# GD32VF103 register map
File version: 1.0
CPU: CM3 r2p1, little endian, no MPU, no FPU, 4 interrupt priority bits
Registers are 32-bit, read-write, reset 0x0 unless marked. A register's access mark holds for its fields unless they carry their own. Offsets are from the block's base; [hi:lo] are bit positions; {n}, {i} and the like mark numbered series.

## FMC
Base 0x40022000
0x00 WS — wait state counter register
  [2:0] WSCNT
0x04 KEY0 wo — Unlock key register 0
  [31:0] KEY — FMC_CTL0 unlock key
0x08 OBKEY wo — Option byte unlock key register
  [31:0] OBKEY — FMC_ CTL0 option byte operation unlock register
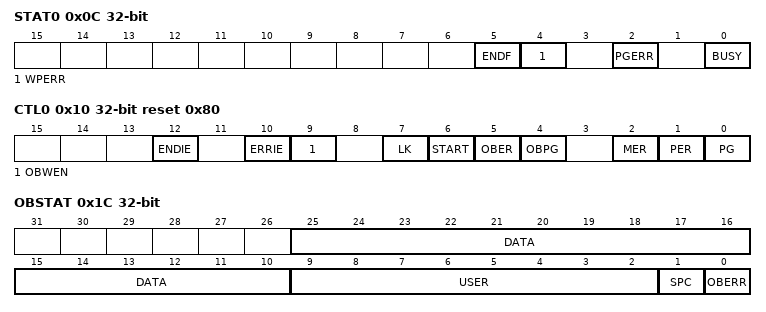
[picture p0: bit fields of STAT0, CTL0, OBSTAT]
0x0C STAT0 access per field — Status register 0
  [5] ENDF rw — End of operation flag bit
  [4] WPERR rw — Erase/Program protection error flag bit
  [2] PGERR rw — Program error flag bit
  [0] BUSY ro — The flash is busy bit
0x10 CTL0 reset 0x80 — Control register 0
  [12] ENDIE — End of operation interrupt enable bit
  [10] ERRIE — Error interrupt enable bit
  [9] OBWEN — Option byte erase/program enable bit
  [7] LK — FMC_CTL0 lock bit
  [6] START — Send erase command to FMC bit
  [5] OBER — Option bytes erase command bit
  [4] OBPG — Option bytes program command bit
  [2] MER — Main flash mass erase for bank0 command bit
  [1] PER — Main flash page erase for bank0 command bit
  [0] PG — Main flash program for bank0 command bit
0x14 ADDR0 wo — Address register 0
  [31:0] ADDR — Flash erase/program command address bits
0x1C OBSTAT ro — Option byte status register
  [25:10] DATA — Store DATA[15:0] of option bytes block after system reset
  [9:2] USER — Store USER of option bytes block after system reset
  [1] SPC — Option bytes security protection code
  [0] OBERR — Option bytes read error bit
0x20 WP ro — Erase/Program Protection register
  [31:0] WP — Store WP[31:0] of option bytes block after system reset
0x100 PID ro — Product ID register
  [31:0] PID — Product reserved ID code register

## FWDGT — free watchdog timer
Base 0x40003000
0x00 CTL wo — Control register
  [15:0] CMD — Key value
0x04 PSC — Prescaler register
  [2:0] PSC — Free watchdog timer prescaler selection
0x08 RLD reset 0xFFF — Reload register
  [11:0] RLD — Free watchdog timer counter reload value
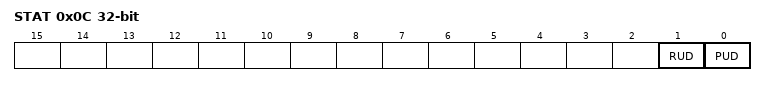
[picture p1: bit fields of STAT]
0x0C STAT ro — Status register
  [1] RUD — Free watchdog timer counter reload value update
  [0] PUD — Free watchdog timer prescaler value update

## GPIOA — General-purpose I/Os
Base 0x40010800
Same registers: GPIOB 0x40010C00, GPIOC 0x40011000, GPIOD 0x40011400, GPIOE 0x40011800
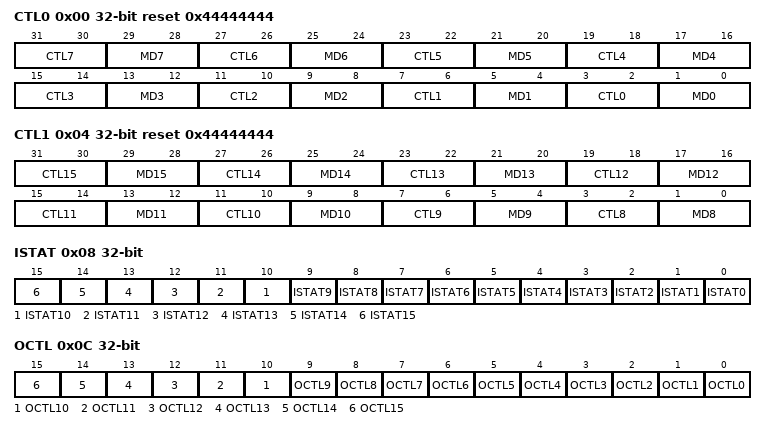
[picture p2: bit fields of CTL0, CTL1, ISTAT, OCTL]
0x00 CTL0 reset 0x44444444 — port control register 0
  [4n+3:4n+2] CTL{n} (n=0..7) — Port x configuration bits (x = {n})
  [4n+1:4n] MD{n} (n=4..7) — Port x mode bits (x = {n})
  [13:12] MD3 — Port x mode bits (x = 3 )
  [9:8] MD2 — Port x mode bits (x = 2 )
  [5:4] MD1 — Port x mode bits (x = 1)
  [1:0] MD0 — Port x mode bits (x = 0)
0x04 CTL1 reset 0x44444444 — port control register 1
  [4n-29:4n-30] CTL{n} (n=8..15) — Port x configuration bits (x = {n})
  [4n-31:4n-32] MD{n} (n=12..15) — Port x mode bits (x = {n})
  [13:12] MD11 — Port x mode bits (x = 11 )
  [9:8] MD10 — Port x mode bits (x = 10 )
  [5:4] MD9 — Port x mode bits (x = 9)
  [1:0] MD8 — Port x mode bits (x = 8)
0x08 ISTAT ro — Port input status register
  [n] ISTAT{n} (n=0..15) — Port input status
0x0C OCTL — Port output control register
  [n] OCTL{n} (n=0..15) — Port output control
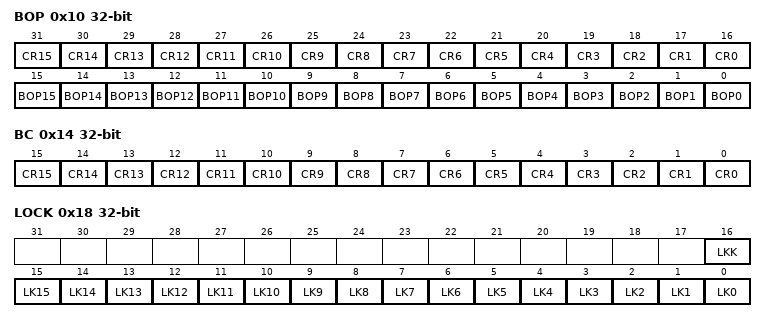
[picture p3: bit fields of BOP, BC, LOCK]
0x10 BOP wo — Port bit operate register
  [n+16] CR{n} (n=0..15) — Port {n} Clear bit
  [n] BOP{n} (n=0..15) — Port {n} Set bit
0x14 BC wo — Port bit clear register
  [n] CR{n} (n=0..15) — Port {n} Clear bit
0x18 LOCK — GPIO port configuration lock register
  [16] LKK — Lock sequence key
  [n] LK{n} (n=0..15) — Port Lock bit {n}

## I2C0 — Inter integrated circuit
Base 0x40005400
Same registers: I2C1 0x40005800
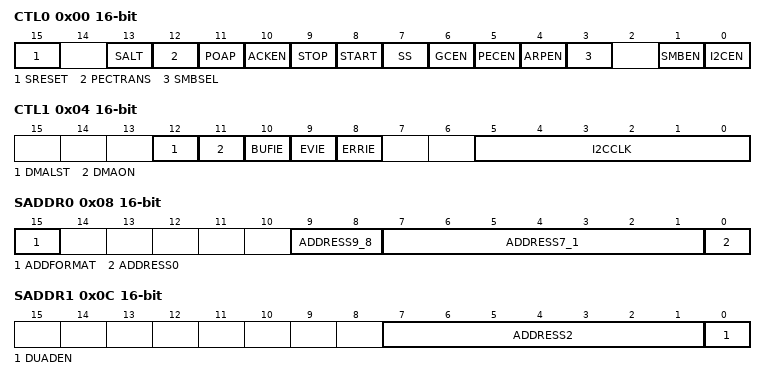
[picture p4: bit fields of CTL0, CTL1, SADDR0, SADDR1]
0x00 CTL0 16-bit — Control register 0
  [15] SRESET — Software reset
  [13] SALT — SMBus alert
  [12] PECTRANS — PEC Transfer
  [11] POAP — Position of ACK and PEC when receiving
  [10] ACKEN — Whether or not to send an ACK
  [9] STOP — Generate a STOP condition on I2C bus
  [8] START — Generate a START condition on I2C bus
  [7] SS — Whether to stretch SCL low when data is not ready in slave mode
  [6] GCEN — Whether or not to response to a General Call (0x00)
  [5] PECEN — PEC Calculation Switch
  [4] ARPEN — ARP protocol in SMBus switch
  [3] SMBSEL — SMBusType Selection
  [1] SMBEN — SMBus/I2C mode switch
  [0] I2CEN — I2C peripheral enable
0x04 CTL1 16-bit — Control register 1
  [12] DMALST — Flag indicating DMA last transfer
  [11] DMAON — DMA mode switch
  [10] BUFIE — Buffer interrupt enable
  [9] EVIE — Event interrupt enable
  [8] ERRIE — Error interrupt enable
  [5:0] I2CCLK — I2C Peripheral clock frequency
0x08 SADDR0 16-bit — Slave address register 0
  [15] ADDFORMAT — Address mode for the I2C slave
  [9:8] ADDRESS9_8 — Highest two bits of a 10-bit address
  [7:1] ADDRESS7_1 — 7-bit address or bits 7:1 of a 10-bit address
  [0] ADDRESS0 — Bit 0 of a 10-bit address
0x0C SADDR1 16-bit — Slave address register 1
  [7:1] ADDRESS2 — Second I2C address for the slave in Dual-Address mode
  [0] DUADEN — Dual-Address mode switch
0x10 DATA 16-bit — Transfer buffer register
  [7:0] TRB — Transmission or reception data buffer register
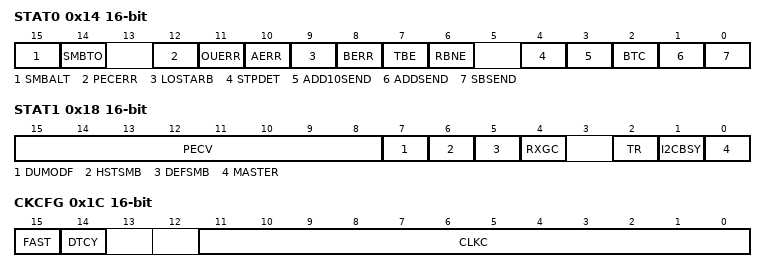
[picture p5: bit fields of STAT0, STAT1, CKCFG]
0x14 STAT0 16-bit access per field — Transfer status register 0
  [15] SMBALT rw — SMBus Alert status
  [14] SMBTO rw — Timeout signal in SMBus mode
  [12] PECERR rw — PEC error when receiving data
  [11] OUERR rw — Over-run or under-run situation occurs in slave mode
  [10] AERR rw — Acknowledge error
  [9] LOSTARB rw — Arbitration Lost in master mode
  [8] BERR rw — A bus error occurs indication a unexpected START or STOP condition on I2C bus
  [7] TBE ro — I2C_DATA is Empty during transmitting
  [6] RBNE ro — I2C_DATA is not Empty during receiving
  [4] STPDET ro — STOP condition detected in slave mode
  [3] ADD10SEND ro — Header of 10-bit address is sent in master mode
  [2] BTC ro — Byte transmission completed
  [1] ADDSEND ro — Address is sent in master mode or received and matches in slave mode
  [0] SBSEND ro — START condition sent out in master mode
0x18 STAT1 16-bit ro — Transfer status register 1
  [15:8] PECV — Packet Error Checking Value that calculated by hardware when PEC is enabled
  [7] DUMODF — Dual Flag in slave mode
  [6] HSTSMB — SMBus Host Header detected in slave mode
  [5] DEFSMB — Default address of SMBusDevice
  [4] RXGC — General call address (00h) received
  [2] TR — Whether the I2C is a transmitter or a receiver
  [1] I2CBSY — Busy flag
  [0] MASTER — A flag indicating whether I2C block is in master or slave mode
0x1C CKCFG 16-bit — Clock configure register
  [15] FAST — I2C speed selection in master mode
  [14] DTCY — Duty cycle in fast mode
  [11:0] CLKC — I2C Clock control in master mode
0x20 RT 16-bit reset 0x2 — Rise time register
  [5:0] RISETIME — Maximum rise time in master mode
